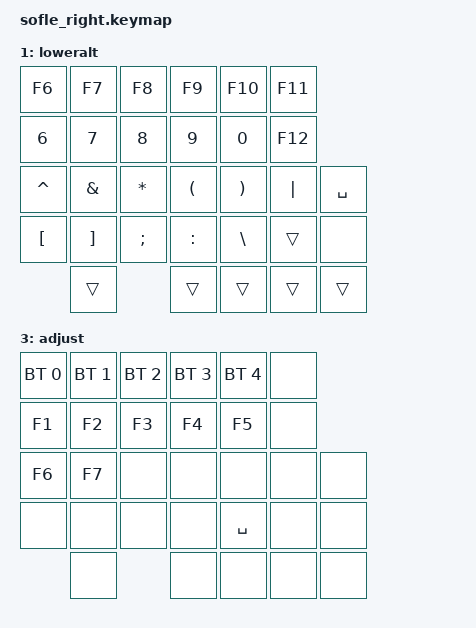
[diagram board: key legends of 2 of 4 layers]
/*
 * Copyright (c) 2020 The ZMK Contributors
 * SPDX-License-Identifier: MIT
 *
 * Sofle Right Half — ZMK v0.3
 * SuperMini NRF52840 (nice_nano_v2) + Sofle PCB
 * neuroman.tech: https://github.com/neuromantech/zmk-config
 *
 * Right half: columns 6-11 + right spacebar.
 * Encoders enabled (raise/adjust layers).
 * RGB underglow NOT enabled — LEDs not soldered yet.
 */

#include <behaviors.dtsi>
#include <dt-bindings/zmk/keys.h>
#include <dt-bindings/zmk/bt.h>
#include <dt-bindings/zmk/ext_power.h>

#define BASE    0
#define LOWERALT 1
#define RAISE   2
#define ADJUST  3

/ {

    conditional_layers {
        compatible = "zmk,conditional-layers";
        adjust_layer {
            if-layers = <LOWERALT RAISE>;
            then-layer = <ADJUST>;
        };
    };

    keymap {
        compatible = "zmk,keymap";

        default_layer {
            display-name = "default";
/*
 * Right half (columns 6-11 + right spacebar)
 *           |  6  |  7  |  8  |  9  |  0  |     |
 *           |  Y  |  U  |  I  |  O  |  P  | BKSPC|
 *           |  H  |  J  |  K  |  L  |  ;  |  '  |
 *           |  N  |  M  |  ,  |  .  |  /  | RSFT |  [RIGHT SPACE HALF]
 *           |RAISE|LCTRL| LALT| LGUI|     |
 */
            bindings = <
&kp N6      &kp N7      &kp N8      &kp N9      &kp N0      &none
&kp Y       &kp U       &kp I       &kp O       &kp P       &kp BSPC
&kp H       &kp J       &kp K       &kp L       &kp SEMI    &kp SQT
&kp N       &kp M       &kp COMMA   &kp DOT     &kp FSLH    &kp RSHFT   &kp SPACE
&mo RAISE   &kp RCTRL   &kp RALT    &kp RGUI    &none
            >;
            sensor-bindings = <&inc_dec_kp PG_UP PG_DN>,
                               <&inc_dec_kp C_VOL_UP C_VOL_DN>;
        };

        loweralt_layer {
            display-name = "loweralt";
/*
 *           | F6  | F7  | F8  | F9  | F10 | F11 |
 *           |  6  |  7  |  8  |  9  |  0  | F12 |
 *           |  ^  |  &  |  *  |  (  |  )  |  |  |
 *           |  [  |  ]  |  ;  |  :  |  \  |     |  [RIGHT SPACE HALF]
 *           |     |     |     |     |     |     |
 */
            bindings = <
&kp F6      &kp F7      &kp F8      &kp F9      &kp F10     &kp F11
&kp N6      &kp N7      &kp N8      &kp N9      &kp N0      &kp F12
&kp CARET   &kp AMPS    &kp ASTRK   &kp LPAR    &kp RPAR    &kp PIPE                         &kp SPACE
&kp LBKT    &kp RBKT    &kp SEMI    &kp COLON   &kp BSLH    &trans    &none
                  &trans       &trans       &trans       &trans      &trans
            >;
            sensor-bindings = <&inc_dec_kp PG_UP PG_DN>,
                               <&inc_dec_kp C_VOL_UP C_VOL_DN>;
        };

        raise_layer {
            display-name = "raise";
/*
 *           |     |     |     |     |     |     |
 *           | PGUP|     |  ^  |     |     |     |
 *           | PGDN| <-  |  v  | ->  | DEL | BKSPC|
 *           |     |     |     |     |     |     |  [RIGHT SPACE HALF]
 *           |     |     |     |     |     |     |
 * Right encoder: scroll + volume in raise layer
 */
            bindings = <
&trans      &trans      &trans      &trans      &trans      &trans                        &none
&kp PG_UP   &trans      &kp UP      &trans      &kp N0      &trans
&kp PG_DN   &kp LEFT    &kp DOWN    &kp RIGHT   &kp DEL     &kp BSPC                      &kp SPACE
&trans      &trans      &trans      &trans      &trans      &trans      &trans  &trans
                  &trans       &trans       &trans       &trans
            >;
            sensor-bindings = <&inc_dec_kp PG_UP PG_DN>,
                               <&inc_dec_kp PG_UP PG_DN>;
        };

        adjust_layer {
            display-name = "adjust";
/*
 *           | BT1   | BT2   | BT3   | BT4   | BT5   |
 *           | F1    | F2    | F3    | F4    | F5    |
 *           | F6    | F7    |       |       |       |
 *           |       |       |       |       |       |  [RIGHT SPACE HALF]
 *           |       |       |       |       |       |
 * Right encoder: brightness / RGB controls in adjust layer
 */
            bindings = <
&bt BT_SEL 0    &bt BT_SEL 1    &bt BT_SEL 2    &bt BT_SEL 3    &bt BT_SEL 4                        &none
&kp F1          &kp F2          &kp F3          &kp F4          &kp F5                              &none
&kp F6          &kp F7          &none           &none           &none                               &none
&none           &none           &none           &none           &none             &kp SPACE   &none &none &none
                                  &none           &none           &none           &none
            >;
            sensor-bindings = <&inc_dec_kp PG_UP PG_DN>,
                               <&inc_dec_kp PG_UP PG_DN>;
        };
    };
};
